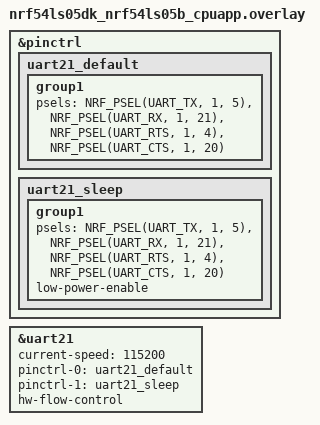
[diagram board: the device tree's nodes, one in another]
&pinctrl {
	uart21_default: uart21_default {
		group1 {
			psels = <NRF_PSEL(UART_TX, 1, 5)>,
				<NRF_PSEL(UART_RX, 1, 21)>,
				<NRF_PSEL(UART_RTS, 1, 4)>,
				<NRF_PSEL(UART_CTS, 1, 20)>;
		};
	};

	uart21_sleep: uart21_sleep {
		group1 {
			psels = <NRF_PSEL(UART_TX, 1, 5)>,
				<NRF_PSEL(UART_RX, 1, 21)>,
				<NRF_PSEL(UART_RTS, 1, 4)>,
				<NRF_PSEL(UART_CTS, 1, 20)>;
			low-power-enable;
		};
	};
};

dut: &uart21 {
	status = "okay";
	current-speed = <115200>;
	pinctrl-0 = <&uart21_default>;
	pinctrl-1 = <&uart21_sleep>;
	pinctrl-names = "default", "sleep";
	hw-flow-control;
};
